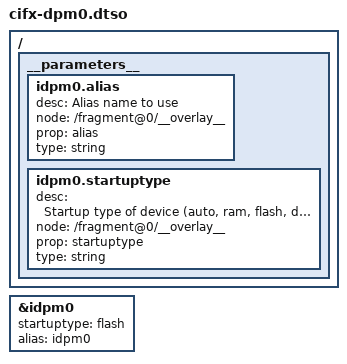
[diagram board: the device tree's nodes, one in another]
/dts-v1/;
/plugin/;

/ {
	fragment@0 {
		target = <&idpm0>;
		__overlay__ {
			status = "okay";
			startuptype = "flash";  /* "auto","ram","flash","donttouch" */
			alias = "idpm0"; /* alias card name */
		};
	};
	__parameters__ {
		idpm0.alias {
			desc = "Alias name to use";
			node = "/fragment@0/__overlay__";
			prop = "alias";
			type = "string";
		};
		idpm0.startuptype {
			desc = "Startup type of device (auto, ram, flash, donttouch)";
			node = "/fragment@0/__overlay__";
			prop = "startuptype";
			type = "string";
		};
	};
};
